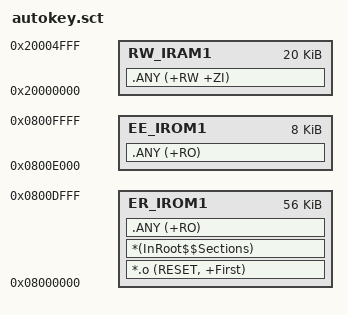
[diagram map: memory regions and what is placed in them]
; *************************************************************
; *** Scatter-Loading Description File generated by uVision ***
; *************************************************************

LR_IROM1 0x08000000 0x0000E000  {    ; load region size_region
  ER_IROM1 0x08000000 0x0000E000  {  ; load address = execution address
   *.o (RESET, +First)
   *(InRoot$$Sections)
   .ANY (+RO)
  }

  RW_IRAM1 0x20000000 0x00005000  {  ; RW data
  .ANY (+RW +ZI)
  }
}

LR_IROM2 0x0800E000 0x00002000  {    ; EEPROM仿真区域 (8KB)
  EE_IROM1 0x0800E000 0x00002000  {  ; EEPROM数据存储
   .ANY (+RO)
  }
}




